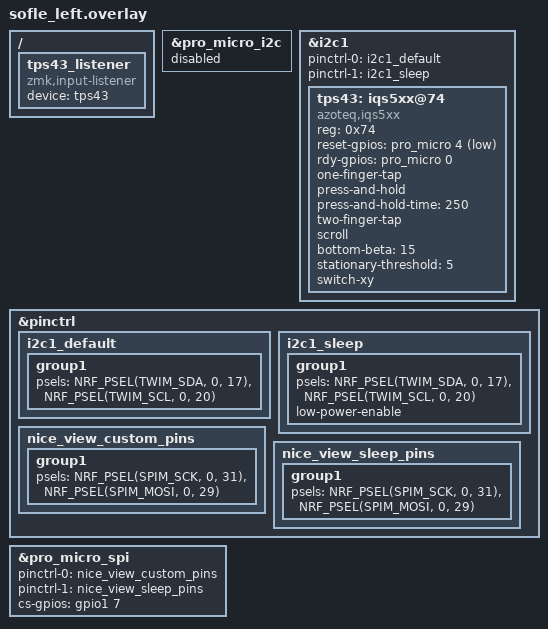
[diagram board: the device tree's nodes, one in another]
#include <dt-bindings/led/led.h>
#include "sofle.dtsi"

/* --- 1. DISABLE CONFLICTS --- */
&pro_micro_i2c { status = "disabled"; };

/* --- 2. CONFIGURE TRACKPAD ON I2C1 --- */
&i2c1 {
    /* DELETE THIS LINE: compatible = "nordic,nrf-twi"; */
    /* Let the board use its default driver (nrf-twim) */
    
    status = "okay";
    
    pinctrl-0 = <&i2c1_default>;
    pinctrl-1 = <&i2c1_sleep>;
    pinctrl-names = "default", "sleep";
    
    tps43: iqs5xx@74 {
        compatible = "azoteq,iqs5xx";
        status = "okay";
        reg = <0x74>;
        reset-gpios = <&pro_micro 4 GPIO_ACTIVE_LOW>;
        rdy-gpios = <&pro_micro 0 GPIO_ACTIVE_HIGH>;
        
        /* Trackpad Settings */
        one-finger-tap;
        press-and-hold;
        press-and-hold-time = <250>;
        two-finger-tap;
        scroll;
        /* natural-scroll-x; */ /* If this errors, comment it out */
        bottom-beta = <15>;
        stationary-threshold = <5>;
        switch-xy;
    };
};

/* --- 3. PIN DEFINITIONS --- */
&pinctrl {
    i2c1_default: i2c1_default {
        group1 { psels = <NRF_PSEL(TWIM_SDA, 0, 17)>, <NRF_PSEL(TWIM_SCL, 0, 20)>; };
    };
    i2c1_sleep: i2c1_sleep {
        group1 { psels = <NRF_PSEL(TWIM_SDA, 0, 17)>, <NRF_PSEL(TWIM_SCL, 0, 20)>; low-power-enable; };
    };

    nice_view_custom_pins: nice_view_custom_pins {
        group1 { 
            psels = <NRF_PSEL(SPIM_SCK, 0, 31)>, 
                    <NRF_PSEL(SPIM_MOSI, 0, 29)>; 
        };
    };

    nice_view_sleep_pins: nice_view_sleep_pins {
        group1 { 
            psels = <NRF_PSEL(SPIM_SCK, 0, 31)>, 
                    <NRF_PSEL(SPIM_MOSI, 0, 29)>; 
            /* REMOVED: low-power-enable; */
        };
    };
};

/* --- 4. CONFIGURE NICE!VIEW (SPI) --- */
&pro_micro_spi {
    status = "okay";
    pinctrl-0 = <&nice_view_custom_pins>;
    pinctrl-1 = <&nice_view_sleep_pins>;
    pinctrl-names = "default", "sleep";
    
    /* Ensure this matches your Nice!View Adapter CS pin */
    cs-gpios = <&gpio1 7 GPIO_ACTIVE_HIGH>;
};

/* --- 5. LISTENERS --- */
/ {
    tps43_listener { compatible = "zmk,input-listener"; device = <&tps43>; };
    
    /* REMOVE THIS LINE IF COMPILING FOR OLD VERSION */
    /* right_input_listener { compatible = "zmk,input-listener"; device = <&right_trackpad_split>; }; */
};
